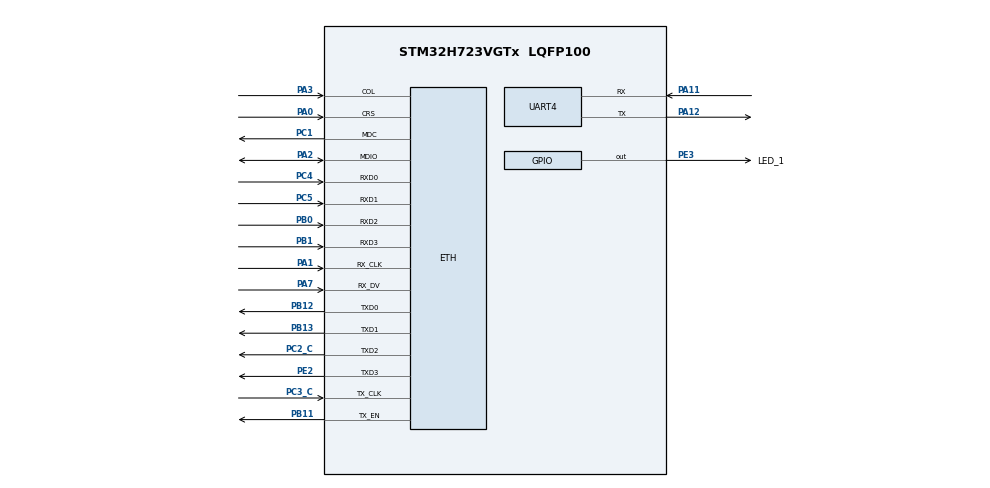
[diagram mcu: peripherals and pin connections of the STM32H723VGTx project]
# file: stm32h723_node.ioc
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CORTEX_M7.CPU_DCache=Disabled
CORTEX_M7.CPU_ICache=Enabled
CORTEX_M7.default_mode_Activation=1
CRC.DefaultPolynomialUse=DEFAULT_POLYNOMIAL_ENABLE
Dma.Request0=UART4_RX
Dma.Request1=UART4_TX
Dma.UART4_RX.0.Direction=DMA_PERIPH_TO_MEMORY
Dma.UART4_RX.0.EventEnable=DISABLE
Dma.UART4_RX.0.FIFOMode=DMA_FIFOMODE_DISABLE
Dma.UART4_RX.0.Instance=DMA1_Stream0
Dma.UART4_RX.0.MemDataAlignment=DMA_MDATAALIGN_BYTE
Dma.UART4_RX.0.MemInc=DMA_MINC_ENABLE
Dma.UART4_RX.0.Mode=DMA_CIRCULAR
Dma.UART4_RX.0.PeriphDataAlignment=DMA_PDATAALIGN_BYTE
Dma.UART4_RX.0.PeriphInc=DMA_PINC_DISABLE
Dma.UART4_RX.0.Polarity=HAL_DMAMUX_REQ_GEN_RISING
Dma.UART4_RX.0.Priority=DMA_PRIORITY_MEDIUM
Dma.UART4_RX.0.RequestNumber=1
Dma.UART4_RX.0.SignalID=NONE
Dma.UART4_RX.0.SyncEnable=DISABLE
Dma.UART4_RX.0.SyncPolarity=HAL_DMAMUX_SYNC_NO_EVENT
Dma.UART4_RX.0.SyncRequestNumber=1
Dma.UART4_RX.0.SyncSignalID=NONE
Dma.UART4_TX.1.Direction=DMA_MEMORY_TO_PERIPH
Dma.UART4_TX.1.EventEnable=DISABLE
Dma.UART4_TX.1.FIFOMode=DMA_FIFOMODE_DISABLE
Dma.UART4_TX.1.Instance=DMA1_Stream1
Dma.UART4_TX.1.MemDataAlignment=DMA_MDATAALIGN_BYTE
Dma.UART4_TX.1.MemInc=DMA_MINC_ENABLE
Dma.UART4_TX.1.Mode=DMA_NORMAL
Dma.UART4_TX.1.PeriphDataAlignment=DMA_PDATAALIGN_BYTE
Dma.UART4_TX.1.PeriphInc=DMA_PINC_DISABLE
Dma.UART4_TX.1.Polarity=HAL_DMAMUX_REQ_GEN_RISING
Dma.UART4_TX.1.Priority=DMA_PRIORITY_MEDIUM
Dma.UART4_TX.1.RequestNumber=1
Dma.UART4_TX.1.SignalID=NONE
Dma.UART4_TX.1.SyncEnable=DISABLE
Dma.UART4_TX.1.SyncPolarity=HAL_DMAMUX_SYNC_NO_EVENT
Dma.UART4_TX.1.SyncRequestNumber=1
Dma.UART4_TX.1.SyncSignalID=NONE
ETH.MediaInterface=HAL_ETH_MII_MODE
FREERTOS.Tasks01=defaultTask,0,1024,StartDefaultTask,Default,NULL,Dynamic,NULL,NULL
FREERTOS.configTOTAL_HEAP_SIZE=45360
FREERTOS.configUSE_NEWLIB_REENTRANT=1
LWIP.BSP.number=1
LWIP.CMSIS_VERSION-Enabled=1
LWIP.GATEWAY_ADDRESS=192.168.000.001
LWIP.IP_ADDRESS=192.168.000.123
LWIP.LWIP_DHCP=0
LWIP.MEM_SIZE=4600
LWIP.NETMASK_ADDRESS=255.255.255.000
LWIP.PPPOE_SUPPORT=0
LWIP.PPPOS_SUPPORT=1
LWIP.PPP_SUPPORT=1
LWIP.Version=v2.1.2_Cube
LWIP0.BSP.STBoard=false
LWIP0.BSP.api=USER_BSP_COMPONENT_DRIVER
LWIP0.BSP.component=USER_PHY
LWIP0.BSP.instance=USER_PHY
LWIP0.BSP.name=Driver_PHY
LWIP0.BSP.semaphore=S_USER_PHY
LWIP0.BSP.solution=USER_PHY
Mcu.Family=STM32H7
Mcu.Name=STM32H723VGTx
Mcu.Package=LQFP100
NVIC.DMA1_Stream0_IRQn=true\:5\:0\:false\:false\:true\:true\:false\:true\:true
NVIC.DMA1_Stream1_IRQn=true\:5\:0\:false\:false\:true\:true\:false\:true\:true
NVIC.ETH_IRQn=true\:5\:0\:false\:false\:true\:true\:true\:true\:true
NVIC.PriorityGroup=NVIC_PRIORITYGROUP_4
NVIC.TIM23_IRQn=true\:15\:0\:false\:false\:true\:false\:false\:true\:true
NVIC.TimeBase=TIM23_IRQn
NVIC.TimeBaseIP=TIM23
NVIC.UART4_IRQn=true\:5\:0\:false\:false\:true\:true\:true\:true\:true
PA0.Mode=MII
PA0.Signal=ETH_CRS
PA1.Mode=MII
PA1.Signal=ETH_RX_CLK
PA11.GPIO_Speed=GPIO_SPEED_FREQ_MEDIUM
PA11.Mode=Asynchronous
PA11.Signal=UART4_RX
PA12.GPIO_Speed=GPIO_SPEED_FREQ_MEDIUM
PA12.Mode=Asynchronous
PA12.Signal=UART4_TX
PA13(JTMS/SWDIO).Mode=Serial_Wire
PA13(JTMS/SWDIO).Signal=DEBUG_JTMS-SWDIO
PA14(JTCK/SWCLK).Mode=Serial_Wire
PA14(JTCK/SWCLK).Signal=DEBUG_JTCK-SWCLK
PA2.Mode=MII
PA2.Signal=ETH_MDIO
PA3.Mode=MII
PA3.Signal=ETH_COL
PA7.Mode=MII
PA7.Signal=ETH_RX_DV
PB0.Mode=MII
PB0.Signal=ETH_RXD2
PB1.Mode=MII
PB1.Signal=ETH_RXD3
PB11.Mode=MII
PB11.Signal=ETH_TX_EN
PB12.Mode=MII
PB12.Signal=ETH_TXD0
PB13.Mode=MII
PB13.Signal=ETH_TXD1
PC1.Mode=MII
PC1.Signal=ETH_MDC
PC14-OSC32_IN.Mode=LSE-External-Oscillator
PC14-OSC32_IN.Signal=RCC_OSC32_IN
PC15-OSC32_OUT.Mode=LSE-External-Oscillator
PC15-OSC32_OUT.Signal=RCC_OSC32_OUT
PC2_C.Mode=MII
PC2_C.Signal=ETH_TXD2
PC3_C.Mode=MII
PC3_C.Signal=ETH_TX_CLK
PC4.Mode=MII
PC4.Signal=ETH_RXD0
PC5.Mode=MII
PC5.Signal=ETH_RXD1
PE2.Mode=MII
PE2.Signal=ETH_TXD3
PE3.GPIO_Label=LED_1
PE3.Signal=GPIO_Output
PH0-OSC_IN.Mode=HSE-External-Oscillator
PH0-OSC_IN.Signal=RCC_OSC_IN
PH1-OSC_OUT.Mode=HSE-External-Oscillator
PH1-OSC_OUT.Signal=RCC_OSC_OUT
ProjectManager.HeapSize=0x200
ProjectManager.StackSize=0x400
ProjectManager.TargetToolchain=STM32CubeIDE
RCC.ADCFreq_Value=129000000
RCC.APB1Freq_Value=137500000
RCC.APB2Freq_Value=137500000
RCC.APB3Freq_Value=137500000
RCC.APB4Freq_Value=137500000
RCC.CortexFreq_Value=550000000
RCC.D1PPRE=RCC_APB3_DIV2
RCC.D2PPRE1=RCC_APB1_DIV2
RCC.D2PPRE2=RCC_APB2_DIV2
RCC.D3PPRE=RCC_APB4_DIV2
RCC.DIVM1=4
RCC.DIVN1=34
RCC.DIVP1=1
RCC.HCLKFreq_Value=275000000
RCC.HPRE=RCC_HCLK_DIV2
RCC.PLLFRACN=3072
RCC.SYSCLKFreq_VALUE=550000000
RCC.SYSCLKSource=RCC_SYSCLKSOURCE_PLLCLK
RCC.USBFreq_Value=275000000
VP_CRC_VS_CRC.Mode=CRC_Activate
VP_FREERTOS_VS_CMSIS_V1.Mode=CMSIS_V1
VP_LWIP_VS_Enabled.Mode=Enabled
VP_MEMORYMAP_VS_MEMORYMAP.Mode=CurAppReg
VP_SYS_VS_tim23.Mode=TIM23
board=custom

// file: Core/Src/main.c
/* USER CODE BEGIN Header */
/**
  ******************************************************************************
  * @file           : main.c
  * @brief          : Main program body
  ******************************************************************************
  * @attention
  *
  * Copyright (c) 2025 STMicroelectronics.
  * All rights reserved.
  *
  * This software is licensed under terms that can be found in the LICENSE file
  * in the root directory of this software component.
  * If no LICENSE file comes with this software, it is provided AS-IS.
  *
  ******************************************************************************
  */
/* USER CODE END Header */
#include "main.h"
#include "cmsis_os.h"
#include "lwip.h"

/* USER CODE BEGIN Includes */

#include "echo.h"
#include "uart.h"

/* USER CODE END Includes */

/* USER CODE BEGIN PD */

#define MAX_MESSAGE_LENGTH 100

/* USER CODE END PD */

CRC_HandleTypeDef hcrc;

UART_HandleTypeDef huart4;
DMA_HandleTypeDef hdma_uart4_rx;
DMA_HandleTypeDef hdma_uart4_tx;

osThreadId defaultTaskHandle;

void SystemClock_Config(void);
static void MPU_Config(void);
static void MX_GPIO_Init(void);
static void MX_DMA_Init(void);
static void MX_CRC_Init(void);
static void MX_UART4_Init(void);
void StartDefaultTask(void const * argument);

int main(void)
{

  /* MPU Configuration--------------------------------------------------------*/
  MPU_Config();

  /* Enable the CPU Cache */

  /* Enable I-Cache---------------------------------------------------------*/
  SCB_EnableICache();

  /* MCU Configuration--------------------------------------------------------*/

  /* Reset of all peripherals, Initializes the Flash interface and the Systick. */
  HAL_Init();

  /* Configure the system clock */
  SystemClock_Config();

  /* Initialize all configured peripherals */
  MX_GPIO_Init();
  MX_DMA_Init();
  MX_CRC_Init();
  MX_UART4_Init();
  /* USER CODE BEGIN 2 */

//  echo_init();

  /* USER CODE END 2 */

  /* Create the thread(s) */
  /* definition and creation of defaultTask */
  osThreadDef(defaultTask, StartDefaultTask, osPriorityNormal, 0, 1024);
  defaultTaskHandle = osThreadCreate(osThread(defaultTask), NULL);

  /* Start scheduler */
  osKernelStart();

  /* We should never get here as control is now taken by the scheduler */

  /* Infinite loop */
  while (1)
  {

  }
}

void SystemClock_Config(void)
{
  RCC_OscInitTypeDef RCC_OscInitStruct = {0};
  RCC_ClkInitTypeDef RCC_ClkInitStruct = {0};

  /** Supply configuration update enable
  */
  HAL_PWREx_ConfigSupply(PWR_LDO_SUPPLY);

  /** Configure the main internal regulator output voltage
  */
  __HAL_PWR_VOLTAGESCALING_CONFIG(PWR_REGULATOR_VOLTAGE_SCALE0);

  while(!__HAL_PWR_GET_FLAG(PWR_FLAG_VOSRDY)) {}

  /** Initializes the RCC Oscillators according to the specified parameters
  * in the RCC_OscInitTypeDef structure.
  */
  RCC_OscInitStruct.OscillatorType = RCC_OSCILLATORTYPE_HSI;
  RCC_OscInitStruct.HSIState = RCC_HSI_DIV1;
  RCC_OscInitStruct.HSICalibrationValue = 64;
  RCC_OscInitStruct.PLL.PLLState = RCC_PLL_ON;
  RCC_OscInitStruct.PLL.PLLSource = RCC_PLLSOURCE_HSI;
  RCC_OscInitStruct.PLL.PLLM = 4;
  RCC_OscInitStruct.PLL.PLLN = 34;
  RCC_OscInitStruct.PLL.PLLP = 1;
  RCC_OscInitStruct.PLL.PLLQ = 2;
  RCC_OscInitStruct.PLL.PLLR = 2;
  RCC_OscInitStruct.PLL.PLLRGE = RCC_PLL1VCIRANGE_3;
  RCC_OscInitStruct.PLL.PLLVCOSEL = RCC_PLL1VCOWIDE;
  RCC_OscInitStruct.PLL.PLLFRACN = 3072;
  if (HAL_RCC_OscConfig(&RCC_OscInitStruct) != HAL_OK)
  {
    Error_Handler();
  }

  /** Initializes the CPU, AHB and APB buses clocks
  */
  RCC_ClkInitStruct.ClockType = RCC_CLOCKTYPE_HCLK|RCC_CLOCKTYPE_SYSCLK
                              |RCC_CLOCKTYPE_PCLK1|RCC_CLOCKTYPE_PCLK2
                              |RCC_CLOCKTYPE_D3PCLK1|RCC_CLOCKTYPE_D1PCLK1;
  RCC_ClkInitStruct.SYSCLKSource = RCC_SYSCLKSOURCE_PLLCLK;
  RCC_ClkInitStruct.SYSCLKDivider = RCC_SYSCLK_DIV1;
  RCC_ClkInitStruct.AHBCLKDivider = RCC_HCLK_DIV2;
  RCC_ClkInitStruct.APB3CLKDivider = RCC_APB3_DIV2;
  RCC_ClkInitStruct.APB1CLKDivider = RCC_APB1_DIV2;
  RCC_ClkInitStruct.APB2CLKDivider = RCC_APB2_DIV2;
  RCC_ClkInitStruct.APB4CLKDivider = RCC_APB4_DIV2;

  if (HAL_RCC_ClockConfig(&RCC_ClkInitStruct, FLASH_LATENCY_3) != HAL_OK)
  {
    Error_Handler();
  }
}

static void MX_CRC_Init(void)
{

  hcrc.Instance = CRC;
  hcrc.Init.DefaultPolynomialUse = DEFAULT_POLYNOMIAL_ENABLE;
  hcrc.Init.DefaultInitValueUse = DEFAULT_INIT_VALUE_ENABLE;
  hcrc.Init.InputDataInversionMode = CRC_INPUTDATA_INVERSION_NONE;
  hcrc.Init.OutputDataInversionMode = CRC_OUTPUTDATA_INVERSION_DISABLE;
  hcrc.InputDataFormat = CRC_INPUTDATA_FORMAT_BYTES;
  if (HAL_CRC_Init(&hcrc) != HAL_OK)
  {
    Error_Handler();
  }

}

static void MX_UART4_Init(void)
{

  huart4.Instance = UART4;
  huart4.Init.BaudRate = 115200;
  huart4.Init.WordLength = UART_WORDLENGTH_8B;
  huart4.Init.StopBits = UART_STOPBITS_1;
  huart4.Init.Parity = UART_PARITY_NONE;
  huart4.Init.Mode = UART_MODE_TX_RX;
  huart4.Init.HwFlowCtl = UART_HWCONTROL_NONE;
  huart4.Init.OverSampling = UART_OVERSAMPLING_16;
  huart4.Init.OneBitSampling = UART_ONE_BIT_SAMPLE_DISABLE;
  huart4.Init.ClockPrescaler = UART_PRESCALER_DIV1;
  huart4.AdvancedInit.AdvFeatureInit = UART_ADVFEATURE_NO_INIT;
  if (HAL_UART_Init(&huart4) != HAL_OK)
  {
    Error_Handler();
  }
  if (HAL_UARTEx_SetTxFifoThreshold(&huart4, UART_TXFIFO_THRESHOLD_1_8) != HAL_OK)
  {
    Error_Handler();
  }
  if (HAL_UARTEx_SetRxFifoThreshold(&huart4, UART_RXFIFO_THRESHOLD_1_8) != HAL_OK)
  {
    Error_Handler();
  }
  if (HAL_UARTEx_DisableFifoMode(&huart4) != HAL_OK)
  {
    Error_Handler();
  }

}

static void MX_DMA_Init(void)
{

  /* DMA controller clock enable */
  __HAL_RCC_DMA1_CLK_ENABLE();

  /* DMA interrupt init */
  /* DMA1_Stream0_IRQn interrupt configuration */
  HAL_NVIC_SetPriority(DMA1_Stream0_IRQn, 5, 0);
  HAL_NVIC_EnableIRQ(DMA1_Stream0_IRQn);
  /* DMA1_Stream1_IRQn interrupt configuration */
  HAL_NVIC_SetPriority(DMA1_Stream1_IRQn, 5, 0);
  HAL_NVIC_EnableIRQ(DMA1_Stream1_IRQn);

}

static void MX_GPIO_Init(void)
{
  GPIO_InitTypeDef GPIO_InitStruct = {0};

  /* GPIO Ports Clock Enable */
  __HAL_RCC_GPIOE_CLK_ENABLE();
  __HAL_RCC_GPIOC_CLK_ENABLE();
  __HAL_RCC_GPIOH_CLK_ENABLE();
  __HAL_RCC_GPIOA_CLK_ENABLE();
  __HAL_RCC_GPIOB_CLK_ENABLE();

  /*Configure GPIO pin Output Level */
  HAL_GPIO_WritePin(LED_1_GPIO_Port, LED_1_Pin, GPIO_PIN_RESET);

  /*Configure GPIO pin : LED_1_Pin */
  GPIO_InitStruct.Pin = LED_1_Pin;
  GPIO_InitStruct.Mode = GPIO_MODE_OUTPUT_PP;
  GPIO_InitStruct.Pull = GPIO_NOPULL;
  GPIO_InitStruct.Speed = GPIO_SPEED_FREQ_LOW;
  HAL_GPIO_Init(LED_1_GPIO_Port, &GPIO_InitStruct);

}

/* USER CODE BEGIN 4 */

/* Return current time in milliseconds */
u32_t sys_now(void) {
    return HAL_GetTick();
}

/* Return number of jiffies (ms since startup) */
u32_t sys_jiffies(void) {
    /* We can simply alias to sys_now */
    return sys_now();
}

/* USER CODE END 4 */

void StartDefaultTask(void const * argument)
{
  /* init code for LWIP */
  MX_LWIP_Init();
  /* USER CODE BEGIN 5 */
  usart_Open();
  MX_LWIP_Init();
  for(;;)
  {
	  HAL_GPIO_TogglePin(LED_1_GPIO_Port, LED_1_Pin);
	  HAL_Delay(20);
  }
  /* USER CODE END 5 */
}

 /* MPU Configuration */

void MPU_Config(void)
{
  MPU_Region_InitTypeDef MPU_InitStruct = {0};

  /* Disables the MPU */
  HAL_MPU_Disable();

  /** Initializes and configures the Region and the memory to be protected
  */
  MPU_InitStruct.Enable = MPU_REGION_ENABLE;
  MPU_InitStruct.Number = MPU_REGION_NUMBER0;
  MPU_InitStruct.BaseAddress = 0x0;
  MPU_InitStruct.Size = MPU_REGION_SIZE_4GB;
  MPU_InitStruct.SubRegionDisable = 0x87;
  MPU_InitStruct.TypeExtField = MPU_TEX_LEVEL0;
  MPU_InitStruct.AccessPermission = MPU_REGION_NO_ACCESS;
  MPU_InitStruct.DisableExec = MPU_INSTRUCTION_ACCESS_DISABLE;
  MPU_InitStruct.IsShareable = MPU_ACCESS_SHAREABLE;
  MPU_InitStruct.IsCacheable = MPU_ACCESS_NOT_CACHEABLE;
  MPU_InitStruct.IsBufferable = MPU_ACCESS_NOT_BUFFERABLE;

  HAL_MPU_ConfigRegion(&MPU_InitStruct);
  /* Enables the MPU */
  HAL_MPU_Enable(MPU_PRIVILEGED_DEFAULT);

}

void HAL_TIM_PeriodElapsedCallback(TIM_HandleTypeDef *htim)
{
  if (htim->Instance == TIM23)
  {
    HAL_IncTick();
  }
}

void Error_Handler(void)
{
  __disable_irq();
  while (1)
  {
  }
}
